AUTOSAR XML (schema 00049)
package /McInt/SwComponents
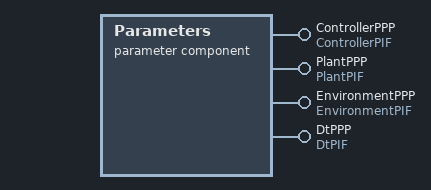
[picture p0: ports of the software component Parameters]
  parameter sw component type Parameters: data-type-mapping=DataTypeMappingSet  # Type for providing the parameters to the ApplicationSwCompoments
    4 x provide port:
      ControllerPPP: provided-interface=ControllerPIF  # Port for providing the parameters for the controller
        provided-com-specs:
          init-value=20 MilliAmperePerKelvinSecond, parameter=ctrl_K
          init-value=2000 KelvinSecond, parameter=ctrl_MaxESum
          init-value=768 DegreeCelsius, parameter=ctrl_SetPoint
      PlantPPP: provided-interface=PlantPIF  # Port for providing the parameters for the plant
        provided-com-specs:
          init-value=1 JoulePerKelvinSecond, parameter=plnt_EnvFactor
          init-value=5 JoulePerMilliAmpereSecond, parameter=plnt_HeaterFactor
      EnvironmentPPP: provided-interface=EnvironmentPIF  # Port for providing the parameters for the environment
        provided-com-specs:
          init-value=300 DegreeCelsius, parameter=env_TLowLimit
          init-value=10 Kelvin, parameter=env_TStepSize
          init-value=200 Kelvin, parameter=env_THighLimitDistance
      DtPPP: parameter-provide-com-spec{init-value=0.1 Second, parameter=Dt}, provided-interface=DtPIF  # Time of one time step
